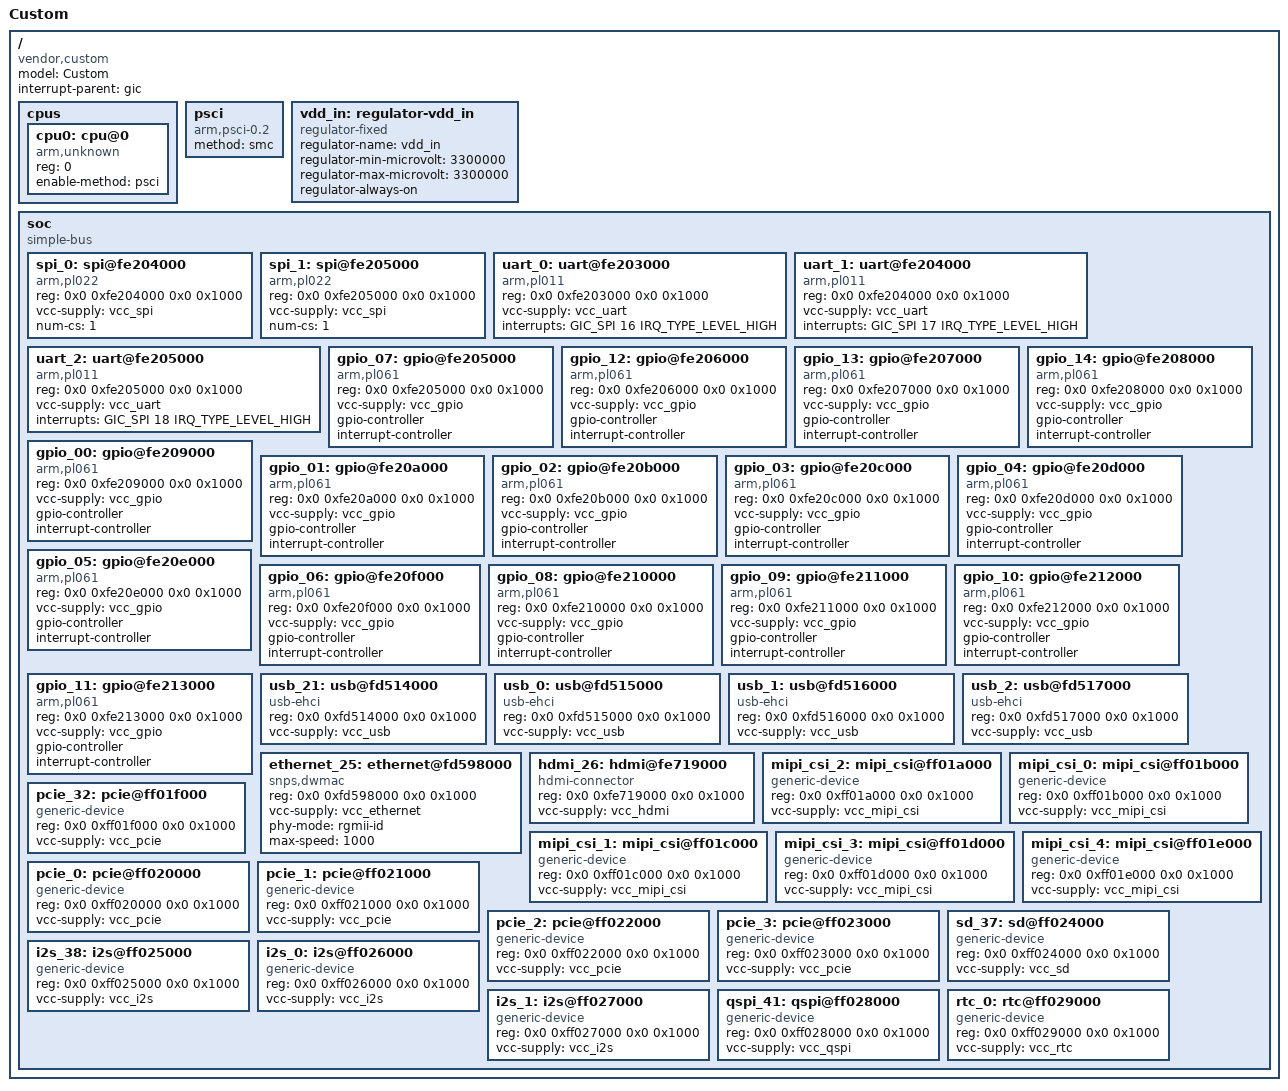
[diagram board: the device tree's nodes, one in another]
/dts-v1/;

/* Generated by @dt_architect — PDF-to-Gadget Pipeline
 * Board: Custom
 * SoC  : Unknown SoC
 * Arch : arm64 (Unknown)
 * Date : auto-generated
 */

#include <dt-bindings/interrupt-controller/arm-gic.h>
#include <dt-bindings/gpio/gpio.h>

/ {
	compatible = "vendor,custom", "vendor,unknown-soc";
	model = "Custom";
	#address-cells = <2>;
	#size-cells = <2>;
	interrupt-parent = <&gic>;

	cpus {
		#address-cells = <1>;
		#size-cells = <0>;

		cpu0: cpu@0 {
			device_type = "cpu";
			compatible = "arm,unknown";
			reg = <0>;
			enable-method = "psci";
		};
	};

	psci {
		compatible = "arm,psci-0.2";
		method = "smc";
	};

	/* ── Power Regulators ─────────────────────────────── */
	vdd_in: regulator-vdd_in {
		compatible = "regulator-fixed";
		regulator-name = "vdd_in";
		regulator-min-microvolt = <3300000>;
		regulator-max-microvolt = <3300000>;
		regulator-always-on;
	};

	/* ── Simple Bus ──────────────────────────────────── */
	soc: soc {
		compatible = "simple-bus";
		#address-cells = <2>;
		#size-cells = <2>;
		ranges;

		spi_0: spi@fe204000 {
			compatible = "arm,pl022";
			reg = <0x0 0xfe204000 0x0 0x1000>;
			#address-cells = <1>;
			#size-cells = <0>;
			status = "okay";
			vcc-supply = <&vcc_spi>;
			/* SPI peripheral on SPI0 */
			#address-cells = <1>;
			#size-cells = <0>;
			clock-names = "spiclk", "apb_pclk";
			num-cs = <1>;
		};

		spi_1: spi@fe205000 {
			compatible = "arm,pl022";
			reg = <0x0 0xfe205000 0x0 0x1000>;
			#address-cells = <1>;
			#size-cells = <0>;
			status = "okay";
			vcc-supply = <&vcc_spi>;
			/* SPI peripheral on SPI1 */
			#address-cells = <1>;
			#size-cells = <0>;
			clock-names = "spiclk", "apb_pclk";
			num-cs = <1>;
		};

		uart_0: uart@fe203000 {
			compatible = "arm,pl011";
			reg = <0x0 0xfe203000 0x0 0x1000>;
			#address-cells = <1>;
			#size-cells = <0>;
			status = "okay";
			vcc-supply = <&vcc_uart>;
			/* UART peripheral on UART0 */
			clock-names = "uartclk", "apb_pclk";
			interrupts = <GIC_SPI 16 IRQ_TYPE_LEVEL_HIGH>;
		};

		uart_1: uart@fe204000 {
			compatible = "arm,pl011";
			reg = <0x0 0xfe204000 0x0 0x1000>;
			#address-cells = <1>;
			#size-cells = <0>;
			status = "okay";
			vcc-supply = <&vcc_uart>;
			/* UART peripheral on UART1 */
			clock-names = "uartclk", "apb_pclk";
			interrupts = <GIC_SPI 17 IRQ_TYPE_LEVEL_HIGH>;
		};

		uart_2: uart@fe205000 {
			compatible = "arm,pl011";
			reg = <0x0 0xfe205000 0x0 0x1000>;
			#address-cells = <1>;
			#size-cells = <0>;
			status = "okay";
			vcc-supply = <&vcc_uart>;
			/* UART peripheral on UART2 */
			clock-names = "uartclk", "apb_pclk";
			interrupts = <GIC_SPI 18 IRQ_TYPE_LEVEL_HIGH>;
		};

		gpio_07: gpio@fe205000 {
			compatible = "arm,pl061";
			reg = <0x0 0xfe205000 0x0 0x1000>;
			#address-cells = <1>;
			#size-cells = <0>;
			status = "okay";
			vcc-supply = <&vcc_gpio>;
			/* GPIO peripheral on GPIO07 */
			gpio-controller;
			#gpio-cells = <2>;
			interrupt-controller;
			#interrupt-cells = <2>;
		};

		gpio_12: gpio@fe206000 {
			compatible = "arm,pl061";
			reg = <0x0 0xfe206000 0x0 0x1000>;
			#address-cells = <1>;
			#size-cells = <0>;
			status = "okay";
			vcc-supply = <&vcc_gpio>;
			/* GPIO peripheral on GPIO12 */
			gpio-controller;
			#gpio-cells = <2>;
			interrupt-controller;
			#interrupt-cells = <2>;
		};

		gpio_13: gpio@fe207000 {
			compatible = "arm,pl061";
			reg = <0x0 0xfe207000 0x0 0x1000>;
			#address-cells = <1>;
			#size-cells = <0>;
			status = "okay";
			vcc-supply = <&vcc_gpio>;
			/* GPIO peripheral on GPIO13 */
			gpio-controller;
			#gpio-cells = <2>;
			interrupt-controller;
			#interrupt-cells = <2>;
		};

		gpio_14: gpio@fe208000 {
			compatible = "arm,pl061";
			reg = <0x0 0xfe208000 0x0 0x1000>;
			#address-cells = <1>;
			#size-cells = <0>;
			status = "okay";
			vcc-supply = <&vcc_gpio>;
			/* GPIO peripheral on GPIO14 */
			gpio-controller;
			#gpio-cells = <2>;
			interrupt-controller;
			#interrupt-cells = <2>;
		};

		gpio_00: gpio@fe209000 {
			compatible = "arm,pl061";
			reg = <0x0 0xfe209000 0x0 0x1000>;
			#address-cells = <1>;
			#size-cells = <0>;
			status = "okay";
			vcc-supply = <&vcc_gpio>;
			/* GPIO peripheral on GPIO00 */
			gpio-controller;
			#gpio-cells = <2>;
			interrupt-controller;
			#interrupt-cells = <2>;
		};

		gpio_01: gpio@fe20a000 {
			compatible = "arm,pl061";
			reg = <0x0 0xfe20a000 0x0 0x1000>;
			#address-cells = <1>;
			#size-cells = <0>;
			status = "okay";
			vcc-supply = <&vcc_gpio>;
			/* GPIO peripheral on GPIO01 */
			gpio-controller;
			#gpio-cells = <2>;
			interrupt-controller;
			#interrupt-cells = <2>;
		};

		gpio_02: gpio@fe20b000 {
			compatible = "arm,pl061";
			reg = <0x0 0xfe20b000 0x0 0x1000>;
			#address-cells = <1>;
			#size-cells = <0>;
			status = "okay";
			vcc-supply = <&vcc_gpio>;
			/* GPIO peripheral on GPIO02 */
			gpio-controller;
			#gpio-cells = <2>;
			interrupt-controller;
			#interrupt-cells = <2>;
		};

		gpio_03: gpio@fe20c000 {
			compatible = "arm,pl061";
			reg = <0x0 0xfe20c000 0x0 0x1000>;
			#address-cells = <1>;
			#size-cells = <0>;
			status = "okay";
			vcc-supply = <&vcc_gpio>;
			/* GPIO peripheral on GPIO03 */
			gpio-controller;
			#gpio-cells = <2>;
			interrupt-controller;
			#interrupt-cells = <2>;
		};

		gpio_04: gpio@fe20d000 {
			compatible = "arm,pl061";
			reg = <0x0 0xfe20d000 0x0 0x1000>;
			#address-cells = <1>;
			#size-cells = <0>;
			status = "okay";
			vcc-supply = <&vcc_gpio>;
			/* GPIO peripheral on GPIO04 */
			gpio-controller;
			#gpio-cells = <2>;
			interrupt-controller;
			#interrupt-cells = <2>;
		};

		gpio_05: gpio@fe20e000 {
			compatible = "arm,pl061";
			reg = <0x0 0xfe20e000 0x0 0x1000>;
			#address-cells = <1>;
			#size-cells = <0>;
			status = "okay";
			vcc-supply = <&vcc_gpio>;
			/* GPIO peripheral on GPIO05 */
			gpio-controller;
			#gpio-cells = <2>;
			interrupt-controller;
			#interrupt-cells = <2>;
		};

		gpio_06: gpio@fe20f000 {
			compatible = "arm,pl061";
			reg = <0x0 0xfe20f000 0x0 0x1000>;
			#address-cells = <1>;
			#size-cells = <0>;
			status = "okay";
			vcc-supply = <&vcc_gpio>;
			/* GPIO peripheral on GPIO06 */
			gpio-controller;
			#gpio-cells = <2>;
			interrupt-controller;
			#interrupt-cells = <2>;
		};

		gpio_08: gpio@fe210000 {
			compatible = "arm,pl061";
			reg = <0x0 0xfe210000 0x0 0x1000>;
			#address-cells = <1>;
			#size-cells = <0>;
			status = "okay";
			vcc-supply = <&vcc_gpio>;
			/* GPIO peripheral on GPIO08 */
			gpio-controller;
			#gpio-cells = <2>;
			interrupt-controller;
			#interrupt-cells = <2>;
		};

		gpio_09: gpio@fe211000 {
			compatible = "arm,pl061";
			reg = <0x0 0xfe211000 0x0 0x1000>;
			#address-cells = <1>;
			#size-cells = <0>;
			status = "okay";
			vcc-supply = <&vcc_gpio>;
			/* GPIO peripheral on GPIO09 */
			gpio-controller;
			#gpio-cells = <2>;
			interrupt-controller;
			#interrupt-cells = <2>;
		};

		gpio_10: gpio@fe212000 {
			compatible = "arm,pl061";
			reg = <0x0 0xfe212000 0x0 0x1000>;
			#address-cells = <1>;
			#size-cells = <0>;
			status = "okay";
			vcc-supply = <&vcc_gpio>;
			/* GPIO peripheral on GPIO10 */
			gpio-controller;
			#gpio-cells = <2>;
			interrupt-controller;
			#interrupt-cells = <2>;
		};

		gpio_11: gpio@fe213000 {
			compatible = "arm,pl061";
			reg = <0x0 0xfe213000 0x0 0x1000>;
			#address-cells = <1>;
			#size-cells = <0>;
			status = "okay";
			vcc-supply = <&vcc_gpio>;
			/* GPIO peripheral on GPIO11 */
			gpio-controller;
			#gpio-cells = <2>;
			interrupt-controller;
			#interrupt-cells = <2>;
		};

		usb_21: usb@fd514000 {
			compatible = "usb-ehci";
			reg = <0x0 0xfd514000 0x0 0x1000>;
			#address-cells = <1>;
			#size-cells = <0>;
			status = "okay";
			vcc-supply = <&vcc_usb>;
			/* USB peripheral on USB */
		};

		usb_0: usb@fd515000 {
			compatible = "usb-ehci";
			reg = <0x0 0xfd515000 0x0 0x1000>;
			#address-cells = <1>;
			#size-cells = <0>;
			status = "okay";
			vcc-supply = <&vcc_usb>;
			/* USB peripheral on USB0 */
		};

		usb_1: usb@fd516000 {
			compatible = "usb-ehci";
			reg = <0x0 0xfd516000 0x0 0x1000>;
			#address-cells = <1>;
			#size-cells = <0>;
			status = "okay";
			vcc-supply = <&vcc_usb>;
			/* USB peripheral on USB1 */
		};

		usb_2: usb@fd517000 {
			compatible = "usb-ehci";
			reg = <0x0 0xfd517000 0x0 0x1000>;
			#address-cells = <1>;
			#size-cells = <0>;
			status = "okay";
			vcc-supply = <&vcc_usb>;
			/* USB peripheral on USB2 */
		};

		ethernet_25: ethernet@fd598000 {
			compatible = "snps,dwmac";
			reg = <0x0 0xfd598000 0x0 0x1000>;
			#address-cells = <1>;
			#size-cells = <0>;
			status = "okay";
			vcc-supply = <&vcc_ethernet>;
			/* ETHERNET peripheral on ETHERNET */
			clock-names = "stmmaceth", "pclk", "ptp_ref";
			phy-mode = "rgmii-id";
			max-speed = <1000>;
		};

		hdmi_26: hdmi@fe719000 {
			compatible = "hdmi-connector";
			reg = <0x0 0xfe719000 0x0 0x1000>;
			#address-cells = <1>;
			#size-cells = <0>;
			status = "okay";
			vcc-supply = <&vcc_hdmi>;
			/* HDMI peripheral on HDMI */
		};

		mipi_csi_2: mipi_csi@ff01a000 {
			compatible = "generic-device";
			reg = <0x0 0xff01a000 0x0 0x1000>;
			#address-cells = <1>;
			#size-cells = <0>;
			status = "okay";
			vcc-supply = <&vcc_mipi_csi>;
			/* MIPI_CSI peripheral on MIPI_CSI2 */
		};

		mipi_csi_0: mipi_csi@ff01b000 {
			compatible = "generic-device";
			reg = <0x0 0xff01b000 0x0 0x1000>;
			#address-cells = <1>;
			#size-cells = <0>;
			status = "okay";
			vcc-supply = <&vcc_mipi_csi>;
			/* MIPI_CSI peripheral on MIPI_CSI0 */
		};

		mipi_csi_1: mipi_csi@ff01c000 {
			compatible = "generic-device";
			reg = <0x0 0xff01c000 0x0 0x1000>;
			#address-cells = <1>;
			#size-cells = <0>;
			status = "okay";
			vcc-supply = <&vcc_mipi_csi>;
			/* MIPI_CSI peripheral on MIPI_CSI1 */
		};

		mipi_csi_3: mipi_csi@ff01d000 {
			compatible = "generic-device";
			reg = <0x0 0xff01d000 0x0 0x1000>;
			#address-cells = <1>;
			#size-cells = <0>;
			status = "okay";
			vcc-supply = <&vcc_mipi_csi>;
			/* MIPI_CSI peripheral on MIPI_CSI3 */
		};

		mipi_csi_4: mipi_csi@ff01e000 {
			compatible = "generic-device";
			reg = <0x0 0xff01e000 0x0 0x1000>;
			#address-cells = <1>;
			#size-cells = <0>;
			status = "okay";
			vcc-supply = <&vcc_mipi_csi>;
			/* MIPI_CSI peripheral on MIPI_CSI4 */
		};

		pcie_32: pcie@ff01f000 {
			compatible = "generic-device";
			reg = <0x0 0xff01f000 0x0 0x1000>;
			#address-cells = <1>;
			#size-cells = <0>;
			status = "okay";
			vcc-supply = <&vcc_pcie>;
			/* PCIE peripheral on PCIE */
		};

		pcie_0: pcie@ff020000 {
			compatible = "generic-device";
			reg = <0x0 0xff020000 0x0 0x1000>;
			#address-cells = <1>;
			#size-cells = <0>;
			status = "okay";
			vcc-supply = <&vcc_pcie>;
			/* PCIE peripheral on PCIE0 */
		};

		pcie_1: pcie@ff021000 {
			compatible = "generic-device";
			reg = <0x0 0xff021000 0x0 0x1000>;
			#address-cells = <1>;
			#size-cells = <0>;
			status = "okay";
			vcc-supply = <&vcc_pcie>;
			/* PCIE peripheral on PCIE1 */
		};

		pcie_2: pcie@ff022000 {
			compatible = "generic-device";
			reg = <0x0 0xff022000 0x0 0x1000>;
			#address-cells = <1>;
			#size-cells = <0>;
			status = "okay";
			vcc-supply = <&vcc_pcie>;
			/* PCIE peripheral on PCIE2 */
		};

		pcie_3: pcie@ff023000 {
			compatible = "generic-device";
			reg = <0x0 0xff023000 0x0 0x1000>;
			#address-cells = <1>;
			#size-cells = <0>;
			status = "okay";
			vcc-supply = <&vcc_pcie>;
			/* PCIE peripheral on PCIE3 */
		};

		sd_37: sd@ff024000 {
			compatible = "generic-device";
			reg = <0x0 0xff024000 0x0 0x1000>;
			#address-cells = <1>;
			#size-cells = <0>;
			status = "okay";
			vcc-supply = <&vcc_sd>;
			/* SD peripheral on SD */
		};

		i2s_38: i2s@ff025000 {
			compatible = "generic-device";
			reg = <0x0 0xff025000 0x0 0x1000>;
			#address-cells = <1>;
			#size-cells = <0>;
			status = "okay";
			vcc-supply = <&vcc_i2s>;
			/* I2S peripheral on I2S */
		};

		i2s_0: i2s@ff026000 {
			compatible = "generic-device";
			reg = <0x0 0xff026000 0x0 0x1000>;
			#address-cells = <1>;
			#size-cells = <0>;
			status = "okay";
			vcc-supply = <&vcc_i2s>;
			/* I2S peripheral on I2S0 */
		};

		i2s_1: i2s@ff027000 {
			compatible = "generic-device";
			reg = <0x0 0xff027000 0x0 0x1000>;
			#address-cells = <1>;
			#size-cells = <0>;
			status = "okay";
			vcc-supply = <&vcc_i2s>;
			/* I2S peripheral on I2S1 */
		};

		qspi_41: qspi@ff028000 {
			compatible = "generic-device";
			reg = <0x0 0xff028000 0x0 0x1000>;
			#address-cells = <1>;
			#size-cells = <0>;
			status = "okay";
			vcc-supply = <&vcc_qspi>;
			/* QSPI peripheral on QSPI */
		};

		rtc_0: rtc@ff029000 {
			compatible = "generic-device";
			reg = <0x0 0xff029000 0x0 0x1000>;
			#address-cells = <1>;
			#size-cells = <0>;
			status = "okay";
			vcc-supply = <&vcc_rtc>;
			/* RTC peripheral on RTC0 */
		};
	};
};
